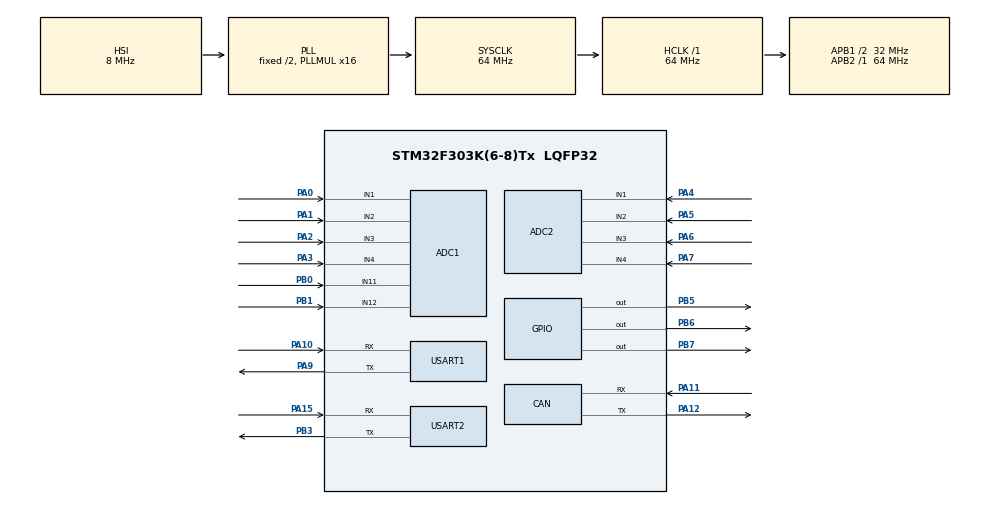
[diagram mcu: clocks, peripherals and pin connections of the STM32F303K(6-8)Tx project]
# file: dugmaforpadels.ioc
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ADC1.Channel-0\#ChannelRegularConversion=ADC_CHANNEL_1
ADC1.NbrOfConversionFlag=1
ADC1.Offset-0\#ChannelRegularConversion=0
ADC1.OffsetNumber-0\#ChannelRegularConversion=ADC_OFFSET_NONE
ADC1.Rank-0\#ChannelRegularConversion=1
ADC1.SamplingTime-0\#ChannelRegularConversion=ADC_SAMPLETIME_1CYCLE_5
ADC1.master=1
ADC2.Channel-0\#ChannelRegularConversion=ADC_CHANNEL_1
ADC2.NbrOfConversionFlag=1
ADC2.Offset-0\#ChannelRegularConversion=0
ADC2.OffsetNumber-0\#ChannelRegularConversion=ADC_OFFSET_NONE
ADC2.Rank-0\#ChannelRegularConversion=1
ADC2.SamplingTime-0\#ChannelRegularConversion=ADC_SAMPLETIME_1CYCLE_5
CAN.CalculateTimeQuantum=500.0
Mcu.Family=STM32F3
Mcu.Name=STM32F303K(6-8)Tx
Mcu.Package=LQFP32
NVIC.PriorityGroup=NVIC_PRIORITYGROUP_4
PA0.Mode=IN1-Single-Ended
PA0.Signal=ADC1_IN1
PA1.Mode=IN2-Single-Ended
PA1.Signal=ADC1_IN2
PA10.Mode=Asynchronous
PA10.Signal=USART1_RX
PA11.Mode=Master
PA11.Signal=CAN_RX
PA12.Mode=Master
PA12.Signal=CAN_TX
PA13.GPIO_Label=SWDIO
PA13.Mode=Serial_Wire
PA13.Signal=SYS_JTMS-SWDIO
PA14.GPIO_Label=SWCLK
PA14.Mode=Serial_Wire
PA14.Signal=SYS_JTCK-SWCLK
PA15.Mode=Asynchronous
PA15.Signal=USART2_RX
PA2.Mode=IN3-Single-Ended
PA2.Signal=ADC1_IN3
PA3.Mode=IN4-Single-Ended
PA3.Signal=ADC1_IN4
PA4.Mode=IN1-Single-Ended
PA4.Signal=ADC2_IN1
PA5.Mode=IN2-Single-Ended
PA5.Signal=ADC2_IN2
PA6.Mode=IN3-Single-Ended
PA6.Signal=ADC2_IN3
PA7.Mode=IN4-Single-Ended
PA7.Signal=ADC2_IN4
PA9.Mode=Asynchronous
PA9.Signal=USART1_TX
PB0.Mode=IN11-Single-Ended
PB0.Signal=ADC1_IN11
PB1.Mode=IN12-Single-Ended
PB1.Signal=ADC1_IN12
PB3.Mode=Asynchronous
PB3.Signal=USART2_TX
PB5.Signal=GPIO_Output
PB6.Signal=GPIO_Output
PB7.Signal=GPIO_Output
PF0\ /\ OSC_IN.GPIO_Label=MCO
PF0\ /\ OSC_IN.Signal=RCC_OSC_IN
ProjectManager.HeapSize=0x200
ProjectManager.StackSize=0x400
ProjectManager.TargetToolchain=SW4STM32
RCC.AHBFreq_Value=64000000
RCC.APB1CLKDivider=RCC_HCLK_DIV2
RCC.APB1Freq_Value=32000000
RCC.APB1TimFreq_Value=64000000
RCC.APB2Freq_Value=64000000
RCC.APB2TimFreq_Value=64000000
RCC.CortexFreq_Value=64000000
RCC.HCLKFreq_Value=64000000
RCC.HSE_VALUE=8000000
RCC.HSI_VALUE=8000000
RCC.PLLMUL=RCC_PLL_MUL16
RCC.SYSCLKFreq_VALUE=64000000
RCC.SYSCLKSourceVirtual=RCC_SYSCLKSOURCE_PLLCLK
USART1.VirtualMode-Asynchronous=VM_ASYNC
USART2.VirtualMode-Asynchronous=VM_ASYNC
VP_TIM6_VS_ClockSourceINT.Mode=Enable_Timer
board=NUCLEO-F303K8

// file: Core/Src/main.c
/* USER CODE BEGIN Header */
/**
  ******************************************************************************
  * @file           : main.c
  * @brief          : Main program body
  ******************************************************************************
  * @attention
  *
  * <h2><center>&copy; Copyright (c) 2020 STMicroelectronics.
  * All rights reserved.</center></h2>
  *
  * This software component is licensed by ST under BSD 3-Clause license,
  * the "License"; You may not use this file except in compliance with the
  * License. You may obtain a copy of the License at:
  *                        opensource.org/licenses/BSD-3-Clause
  *
  ******************************************************************************
  */
/* USER CODE END Header */
#include "main.h"
#include <string.h>
#include <stdio.h>

ADC_HandleTypeDef hadc1;
ADC_HandleTypeDef hadc2;

CAN_HandleTypeDef hcan;

TIM_HandleTypeDef htim6;

UART_HandleTypeDef huart1;
UART_HandleTypeDef huart2;
char msg[100] = {0};

void SystemClock_Config(void);
static void MX_GPIO_Init(void);
static void MX_ADC1_Init(void);
static void MX_ADC2_Init(void);
static void MX_CAN_Init(void);
static void MX_TIM6_Init(void);
static void MX_USART1_UART_Init(void);
static void MX_USART2_UART_Init(void);

int main(void)
{

  /* MCU Configuration--------------------------------------------------------*/

  /* Reset of all peripherals, Initializes the Flash interface and the Systick. */
  HAL_Init();

  /* Configure the system clock */
  SystemClock_Config();

  /* Initialize all configured peripherals */
  MX_GPIO_Init();
  MX_ADC1_Init();
  MX_ADC2_Init();
  MX_CAN_Init();
  MX_TIM6_Init();
  MX_USART1_UART_Init();
  MX_USART2_UART_Init();

  /* Infinite loop */
  while (1)
  {
	  sprintf(msg,"Hello World!  \r\n");
	  HAL_UART_Transmit(&huart1,(uint8_t*)msg,strlen(msg),HAL_MAX_DELAY);
	  HAL_Delay(200);
  }
}

void SystemClock_Config(void)
{
  RCC_OscInitTypeDef RCC_OscInitStruct = {0};
  RCC_ClkInitTypeDef RCC_ClkInitStruct = {0};
  RCC_PeriphCLKInitTypeDef PeriphClkInit = {0};

  /** Initializes the RCC Oscillators according to the specified parameters
  * in the RCC_OscInitTypeDef structure.
  */
  RCC_OscInitStruct.OscillatorType = RCC_OSCILLATORTYPE_HSI;
  RCC_OscInitStruct.HSIState = RCC_HSI_ON;
  RCC_OscInitStruct.HSICalibrationValue = RCC_HSICALIBRATION_DEFAULT;
  RCC_OscInitStruct.PLL.PLLState = RCC_PLL_ON;
  RCC_OscInitStruct.PLL.PLLSource = RCC_PLLSOURCE_HSI;
  RCC_OscInitStruct.PLL.PLLMUL = RCC_PLL_MUL16;
  if (HAL_RCC_OscConfig(&RCC_OscInitStruct) != HAL_OK)
  {
    Error_Handler();
  }
  /** Initializes the CPU, AHB and APB buses clocks
  */
  RCC_ClkInitStruct.ClockType = RCC_CLOCKTYPE_HCLK|RCC_CLOCKTYPE_SYSCLK
                              |RCC_CLOCKTYPE_PCLK1|RCC_CLOCKTYPE_PCLK2;
  RCC_ClkInitStruct.SYSCLKSource = RCC_SYSCLKSOURCE_PLLCLK;
  RCC_ClkInitStruct.AHBCLKDivider = RCC_SYSCLK_DIV1;
  RCC_ClkInitStruct.APB1CLKDivider = RCC_HCLK_DIV2;
  RCC_ClkInitStruct.APB2CLKDivider = RCC_HCLK_DIV1;

  if (HAL_RCC_ClockConfig(&RCC_ClkInitStruct, FLASH_LATENCY_2) != HAL_OK)
  {
    Error_Handler();
  }
  PeriphClkInit.PeriphClockSelection = RCC_PERIPHCLK_USART1|RCC_PERIPHCLK_ADC12;
  PeriphClkInit.Usart1ClockSelection = RCC_USART1CLKSOURCE_PCLK1;
  PeriphClkInit.Adc12ClockSelection = RCC_ADC12PLLCLK_DIV1;
  if (HAL_RCCEx_PeriphCLKConfig(&PeriphClkInit) != HAL_OK)
  {
    Error_Handler();
  }
}

static void MX_ADC1_Init(void)
{

  ADC_MultiModeTypeDef multimode = {0};
  ADC_ChannelConfTypeDef sConfig = {0};

  /** Common config
  */
  hadc1.Instance = ADC1;
  hadc1.Init.ClockPrescaler = ADC_CLOCK_ASYNC_DIV1;
  hadc1.Init.Resolution = ADC_RESOLUTION_12B;
  hadc1.Init.ScanConvMode = ADC_SCAN_DISABLE;
  hadc1.Init.ContinuousConvMode = DISABLE;
  hadc1.Init.DiscontinuousConvMode = DISABLE;
  hadc1.Init.ExternalTrigConvEdge = ADC_EXTERNALTRIGCONVEDGE_NONE;
  hadc1.Init.ExternalTrigConv = ADC_SOFTWARE_START;
  hadc1.Init.DataAlign = ADC_DATAALIGN_RIGHT;
  hadc1.Init.NbrOfConversion = 1;
  hadc1.Init.DMAContinuousRequests = DISABLE;
  hadc1.Init.EOCSelection = ADC_EOC_SINGLE_CONV;
  hadc1.Init.LowPowerAutoWait = DISABLE;
  hadc1.Init.Overrun = ADC_OVR_DATA_OVERWRITTEN;
  if (HAL_ADC_Init(&hadc1) != HAL_OK)
  {
    Error_Handler();
  }
  /** Configure the ADC multi-mode
  */
  multimode.Mode = ADC_MODE_INDEPENDENT;
  if (HAL_ADCEx_MultiModeConfigChannel(&hadc1, &multimode) != HAL_OK)
  {
    Error_Handler();
  }
  /** Configure Regular Channel
  */
  sConfig.Channel = ADC_CHANNEL_1;
  sConfig.Rank = ADC_REGULAR_RANK_1;
  sConfig.SingleDiff = ADC_SINGLE_ENDED;
  sConfig.SamplingTime = ADC_SAMPLETIME_1CYCLE_5;
  sConfig.OffsetNumber = ADC_OFFSET_NONE;
  sConfig.Offset = 0;
  if (HAL_ADC_ConfigChannel(&hadc1, &sConfig) != HAL_OK)
  {
    Error_Handler();
  }

}

static void MX_ADC2_Init(void)
{

  ADC_ChannelConfTypeDef sConfig = {0};

  /** Common config
  */
  hadc2.Instance = ADC2;
  hadc2.Init.ClockPrescaler = ADC_CLOCK_ASYNC_DIV1;
  hadc2.Init.Resolution = ADC_RESOLUTION_12B;
  hadc2.Init.ScanConvMode = ADC_SCAN_DISABLE;
  hadc2.Init.ContinuousConvMode = DISABLE;
  hadc2.Init.DiscontinuousConvMode = DISABLE;
  hadc2.Init.ExternalTrigConvEdge = ADC_EXTERNALTRIGCONVEDGE_NONE;
  hadc2.Init.ExternalTrigConv = ADC_SOFTWARE_START;
  hadc2.Init.DataAlign = ADC_DATAALIGN_RIGHT;
  hadc2.Init.NbrOfConversion = 1;
  hadc2.Init.DMAContinuousRequests = DISABLE;
  hadc2.Init.EOCSelection = ADC_EOC_SINGLE_CONV;
  hadc2.Init.LowPowerAutoWait = DISABLE;
  hadc2.Init.Overrun = ADC_OVR_DATA_OVERWRITTEN;
  if (HAL_ADC_Init(&hadc2) != HAL_OK)
  {
    Error_Handler();
  }
  /** Configure Regular Channel
  */
  sConfig.Channel = ADC_CHANNEL_1;
  sConfig.Rank = ADC_REGULAR_RANK_1;
  sConfig.SingleDiff = ADC_SINGLE_ENDED;
  sConfig.SamplingTime = ADC_SAMPLETIME_1CYCLE_5;
  sConfig.OffsetNumber = ADC_OFFSET_NONE;
  sConfig.Offset = 0;
  if (HAL_ADC_ConfigChannel(&hadc2, &sConfig) != HAL_OK)
  {
    Error_Handler();
  }

}

static void MX_CAN_Init(void)
{

  hcan.Instance = CAN;
  hcan.Init.Prescaler = 16;
  hcan.Init.Mode = CAN_MODE_NORMAL;
  hcan.Init.SyncJumpWidth = CAN_SJW_1TQ;
  hcan.Init.TimeSeg1 = CAN_BS1_1TQ;
  hcan.Init.TimeSeg2 = CAN_BS2_1TQ;
  hcan.Init.TimeTriggeredMode = DISABLE;
  hcan.Init.AutoBusOff = DISABLE;
  hcan.Init.AutoWakeUp = DISABLE;
  hcan.Init.AutoRetransmission = DISABLE;
  hcan.Init.ReceiveFifoLocked = DISABLE;
  hcan.Init.TransmitFifoPriority = DISABLE;
  if (HAL_CAN_Init(&hcan) != HAL_OK)
  {
    Error_Handler();
  }

}

static void MX_TIM6_Init(void)
{

  TIM_MasterConfigTypeDef sMasterConfig = {0};

  htim6.Instance = TIM6;
  htim6.Init.Prescaler = 0;
  htim6.Init.CounterMode = TIM_COUNTERMODE_UP;
  htim6.Init.Period = 65535;
  htim6.Init.AutoReloadPreload = TIM_AUTORELOAD_PRELOAD_DISABLE;
  if (HAL_TIM_Base_Init(&htim6) != HAL_OK)
  {
    Error_Handler();
  }
  sMasterConfig.MasterOutputTrigger = TIM_TRGO_RESET;
  sMasterConfig.MasterSlaveMode = TIM_MASTERSLAVEMODE_DISABLE;
  if (HAL_TIMEx_MasterConfigSynchronization(&htim6, &sMasterConfig) != HAL_OK)
  {
    Error_Handler();
  }

}

static void MX_USART1_UART_Init(void)
{

  huart1.Instance = USART1;
  huart1.Init.BaudRate = 38400;
  huart1.Init.WordLength = UART_WORDLENGTH_8B;
  huart1.Init.StopBits = UART_STOPBITS_1;
  huart1.Init.Parity = UART_PARITY_NONE;
  huart1.Init.Mode = UART_MODE_TX_RX;
  huart1.Init.HwFlowCtl = UART_HWCONTROL_NONE;
  huart1.Init.OverSampling = UART_OVERSAMPLING_16;
  huart1.Init.OneBitSampling = UART_ONE_BIT_SAMPLE_DISABLE;
  huart1.AdvancedInit.AdvFeatureInit = UART_ADVFEATURE_NO_INIT;
  if (HAL_UART_Init(&huart1) != HAL_OK)
  {
    Error_Handler();
  }

}

static void MX_USART2_UART_Init(void)
{

  huart2.Instance = USART2;
  huart2.Init.BaudRate = 38400;
  huart2.Init.WordLength = UART_WORDLENGTH_8B;
  huart2.Init.StopBits = UART_STOPBITS_1;
  huart2.Init.Parity = UART_PARITY_NONE;
  huart2.Init.Mode = UART_MODE_TX_RX;
  huart2.Init.HwFlowCtl = UART_HWCONTROL_NONE;
  huart2.Init.OverSampling = UART_OVERSAMPLING_16;
  huart2.Init.OneBitSampling = UART_ONE_BIT_SAMPLE_DISABLE;
  huart2.AdvancedInit.AdvFeatureInit = UART_ADVFEATURE_NO_INIT;
  if (HAL_UART_Init(&huart2) != HAL_OK)
  {
    Error_Handler();
  }

}

static void MX_GPIO_Init(void)
{
  GPIO_InitTypeDef GPIO_InitStruct = {0};

  /* GPIO Ports Clock Enable */
  __HAL_RCC_GPIOF_CLK_ENABLE();
  __HAL_RCC_GPIOA_CLK_ENABLE();
  __HAL_RCC_GPIOB_CLK_ENABLE();

  /*Configure GPIO pin Output Level */
  HAL_GPIO_WritePin(GPIOB, GPIO_PIN_5|GPIO_PIN_6|GPIO_PIN_7, GPIO_PIN_RESET);

  /*Configure GPIO pins : PB5 PB6 PB7 */
  GPIO_InitStruct.Pin = GPIO_PIN_5|GPIO_PIN_6|GPIO_PIN_7;
  GPIO_InitStruct.Mode = GPIO_MODE_OUTPUT_PP;
  GPIO_InitStruct.Pull = GPIO_NOPULL;
  GPIO_InitStruct.Speed = GPIO_SPEED_FREQ_LOW;
  HAL_GPIO_Init(GPIOB, &GPIO_InitStruct);

}

void Error_Handler(void)
{
  /* USER CODE BEGIN Error_Handler_Debug */
  /* User can add his own implementation to report the HAL error return state */
while(1);
  /* USER CODE END Error_Handler_Debug */
}

/************************ (C) COPYRIGHT STMicroelectronics *****END OF FILE****/
